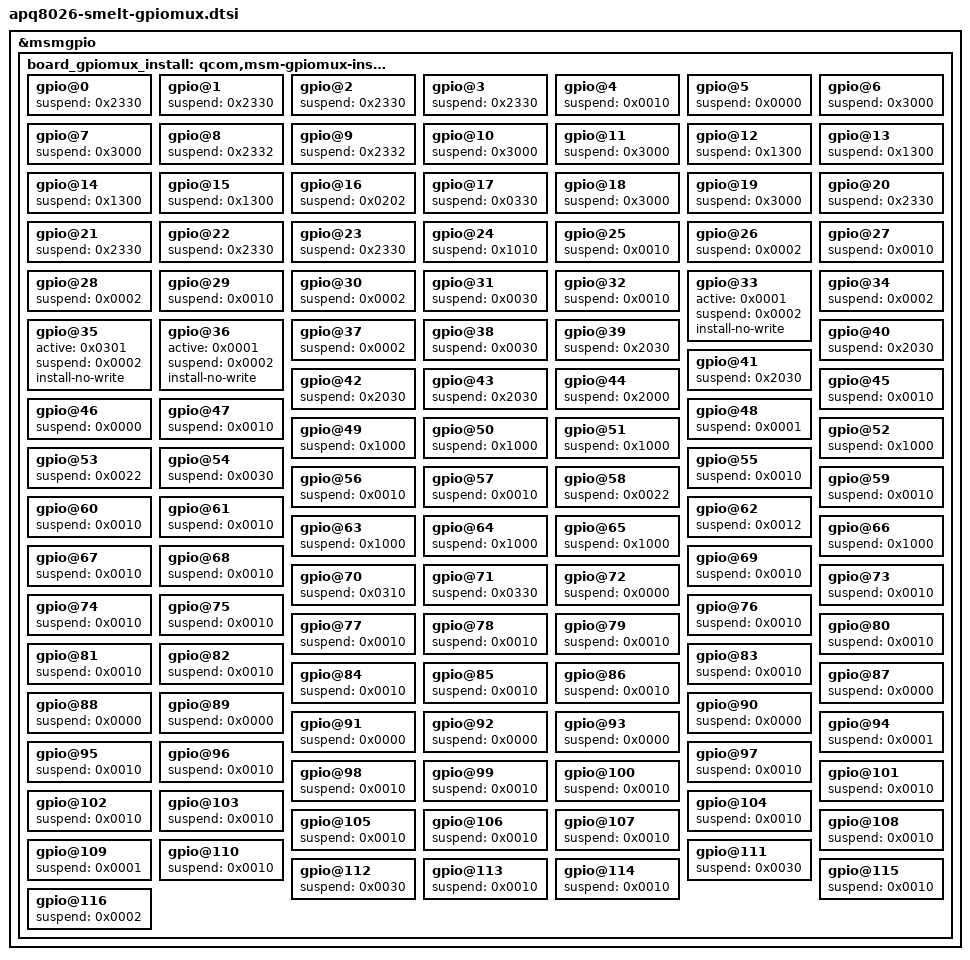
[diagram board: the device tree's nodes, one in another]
/* Copyright (c) 2014, The Linux Foundation. All rights reserved.
 *
 * This program is free software; you can redistribute it and/or modify
 * it under the terms of the GNU General Public License version 2 and
 * only version 2 as published by the Free Software Foundation.
 *
 * This program is distributed in the hope that it will be useful,
 * but WITHOUT ANY WARRANTY; without even the implied warranty of
 * MERCHANTABILITY or FITNESS FOR A PARTICULAR PURPOSE.  See the
 * GNU General Public License for more details.
 */

&msmgpio {
	/* board gpiomux initialization
	 * each node format is:
	 *   gpio-xx {
	 *     active = < gpio_settings >;
	 *     suspend = < gpio_settings >;
	 *     install-no-write;
	 *   };
	 * which xx is gpio digit number which needed to set.
	 *   active is the settings when gpio is requested.
	 *   suspend is the settings when gpio is freed. and gpiomux-install
	 *     will write suspend_settings as there is not any gpio had been
	 *     requested at beginning.
	 *   install-no-write is bool that indicates not change current state
	 *     of hardware, which is needed for some case like display, it
	 *     needs keep current settings from boot-loader
	 * gpio_settings is 16 bits hex like 0xFVPD, please refer kernel code
	 *   definition in gpiomux.h
	 *   'D' bits 0-3 is gpio direction and value, which
	 *       0 = input, 1 = output high, 2 = output low,
	 *   'P' bits 4-7 is gpio pull method, which
	 *       0 = none, 1 = pull down, 2 = pull keeper, 3 = pull up,
	 *   'V' bits 8-11 is gpio driven, which
	 *       0 = 2 mA, 1 = 4 mA, n = (n+1)*2 mA, the maximum is 16mA
	 *   'F' bits 12-15 is gpio function, which
	 *       0 = gpio, others refer hardware reference
	 * Example:
	 *
	 */
	board_gpiomux_install: qcom,msm-gpiomux-install {
		gpio@0 {
			suspend = <0x2330>; /* FUNC_2, DRV_8MA, PULL_UP, IN */
		};
		gpio@1 {
			suspend = <0x2330>; /* FUNC_2, DRV_8MA, PULL_UP, IN */
		};
		gpio@2 {
			suspend = <0x2330>; /* FUNC_2, DRV_8MA, PULL_UP, IN */
		};
		gpio@3 {
			suspend = <0x2330>; /* FUNC_2, DRV_8MA, PULL_UP, IN */
		};
		gpio@4 {
			suspend = <0x0010>; /* FUNC_GPIO, DRV_2MA, PULL_DOWN, IN */
		};
		gpio@5 {
			suspend = <0x0000>; /* FUNC_GPIO, DRV_2MA, PULL_NONE, IN */
		};
		gpio@6 {
			suspend = <0x3000>; /* FUNC_3, DRV_2MA, PULL_NONE, IN */
		};
		gpio@7 {
			suspend = <0x3000>; /* FUNC_3, DRV_2MA, PULL_NONE, IN */
		};
		gpio@8 {
			suspend = <0x2332>; /* FUNC_2, DRV_8MA, PULL_UP, OUT_LOW */
		};
		gpio@9 {
			suspend = <0x2332>; /* FUNC_2, DRV_8MA, PULL_UP, OUT_LOW */
		};
		gpio@10 {
			suspend = <0x3000>; /* FUNC_3, DRV_2MA, PULL_NONE, IN */
		};
		gpio@11 {
			suspend = <0x3000>; /* FUNC_3, DRV_2MA, PULL_NONE, IN */
		};
		gpio@12 {
			suspend = <0x1300>; /* FUNC_1, DRV_8MA, PULL_NONE, IN */
		};
		gpio@13 {
			suspend = <0x1300>; /* FUNC_1, DRV_8MA, PULL_NONE, IN */
		};
		gpio@14 {
			suspend = <0x1300>; /* FUNC_1, DRV_8MA, PULL_NONE, IN */
		};
		gpio@15 {
			suspend = <0x1300>; /* FUNC_1, DRV_8MA, PULL_NONE, IN */
		};
		gpio@16 {
			suspend = <0x0202>; /* FUNC_GPIO, DRV_6MA, PULL_NONE, OUT_LOW */
		};
		gpio@17 {
			suspend = <0x0330>; /* FUNC_GPIO, DRV_8MA, PULL_UP, IN */
		};
		gpio@18 {
			suspend = <0x3000>; /* FUNC_3, DRV_2MA, PULL_NONE, IN */
		};
		gpio@19 {
			suspend = <0x3000>; /* FUNC_3, DRV_2MA, PULL_NONE, IN */
		};
		gpio@20 {
			suspend = <0x2330>; /* FUNC_2, DRV_8MA, PULL_UP, IN */
		};
		gpio@21 {
			suspend = <0x2330>; /* FUNC_2, DRV_8MA, PULL_UP, IN */
		};
		gpio@22 {
			suspend = <0x2330>; /* FUNC_2, DRV_8MA, PULL_UP, IN */
		};
		gpio@23 {
			suspend = <0x2330>; /* FUNC_2, DRV_8MA, PULL_UP, IN */
		};
		gpio@24 {
			suspend = <0x1010>; /* FUNC_1, DRV_2MA, PULL_DOWN, IN */
		};
		gpio@25 {
			suspend = <0x0010>; /* FUNC_GPIO, DRV_2MA, PULL_DOWN, IN */
		};
		gpio@26 {
			suspend = <0x0002>; /* FUNC_GPIO, DRV_2MA, PULL_NONE, OUT_LOW */
		};
		gpio@27 {
			suspend = <0x0010>; /* FUNC_GPIO, DRV_2MA, PULL_DOWN, IN */
		};
		gpio@28 {
			suspend = <0x0002>; /* FUNC_GPIO, DRV_2MA, PULL_NONE, OUT_LOW */
		};
		gpio@29 {
			suspend = <0x0010>; /* FUNC_GPIO, DRV_2MA, PULL_DOWN, IN */
		};
		gpio@30 {
			suspend = <0x0002>; /* FUNC_GPIO, DRV_2MA, PULL_NONE, OUT_LOW */
		};
		gpio@31 {
			suspend = <0x0030>; /* FUNC_GPIO, DRV_2MA, PULL_UP, IN */
		};
		gpio@32 {
			suspend = <0x0010>; /* FUNC_GPIO, DRV_2MA, PULL_DOWN, IN */
		};
		gpio@33 {
			active  = <0x0001>; /* FUNC_GPIO, DRV_2MA, PULL_NONE, OUT_HIGH */
			suspend = <0x0002>; /* FUNC_GPIO, DRV_2MA, PULL_NONE, OUT_LOW */
			install-no-write;
		};
		gpio@34 {
			suspend = <0x0002>; /* FUNC_GPIO, DRV_2MA, PULL_NONE, OUT_LOW */
		};
		gpio@35 {
			active  = <0x0301>; /* FUNC_GPIO, DRV_8MA, PULL_NONE, OUT_HIGH */
			suspend = <0x0002>; /* FUNC_GPIO, DRV_2MA, PULL_NONE, OUT_LOW */
			install-no-write;
		};
		gpio@36 {
			active  = <0x0001>; /* FUNC_GPIO, DRV_2MA, PULL_NONE, OUT_HIGH */
			suspend = <0x0002>; /* FUNC_GPIO, DRV_2MA, PULL_NONE, OUT_LOW */
			install-no-write;
		};
		gpio@37 {
			suspend = <0x0002>; /* FUNC_GPIO, DRV_2MA, PULL_NONE, OUT_LOW */
		};
		gpio@38 {
			suspend = <0x0030>; /* FUNC_GPIO, DRV_2MA, PULL_UP, IN */
		};
		gpio@39 {
			suspend = <0x2030>; /* FUNC_2, DRV_2MA, PULL_UP, IN */
		};
		gpio@40 {
			suspend = <0x2030>; /* FUNC_2, DRV_2MA, PULL_UP, IN */
		};
		gpio@41 {
			suspend = <0x2030>; /* FUNC_2, DRV_2MA, PULL_UP, IN */
		};
		gpio@42 {
			suspend = <0x2030>; /* FUNC_2, DRV_2MA, PULL_UP, IN */
		};
		gpio@43 {
			suspend = <0x2030>; /* FUNC_2, DRV_2MA, PULL_UP, IN */
		};
		gpio@44 {
			suspend = <0x2000>; /* FUNC_2, DRV_2MA, PULL_NONE, IN */
		};
		gpio@45 {
			suspend = <0x0010>; /* FUNC_GPIO, DRV_2MA, PULL_DOWN, IN */
		};
		gpio@46 {
			suspend = <0x0000>; /* FUNC_GPIO, DRV_2MA, PULL_NONE, IN */
		};
		gpio@47 {
			suspend = <0x0010>; /* FUNC_GPIO, DRV_2MA, PULL_DOWN, IN */
		};
		gpio@48 {
			suspend = <0x0001>; /* FUNC_GPIO, DRV_2MA, PULL_NONE, OUT_HIGH */
		};
		gpio@49 {
			suspend = <0x1000>; /* FUNC_1, DRV_2MA, PULL_NONE, IN */
		};
		gpio@50 {
			suspend = <0x1000>; /* FUNC_1, DRV_2MA, PULL_NONE, IN */
		};
		gpio@51 {
			suspend = <0x1000>; /* FUNC_1, DRV_2MA, PULL_NONE, IN */
		};
		gpio@52 {
			suspend = <0x1000>; /* FUNC_1, DRV_2MA, PULL_NONE, IN */
		};
		gpio@53 {
			suspend = <0x0022>; /* FUNC_GPIO, DRV_2MA, PULL_KEEPER, OUT_LOW */
		};
		gpio@54 {
			suspend = <0x0030>; /* FUNC_GPIO, DRV_2MA, PULL_UP, IN */
		};
		gpio@55 {
			suspend = <0x0010>; /* FUNC_GPIO, DRV_2MA, PULL_DOWN, IN */
		};
		gpio@56 {
			suspend = <0x0010>; /* FUNC_GPIO, DRV_2MA, PULL_DOWN, IN */
		};
		gpio@57 {
			suspend = <0x0010>; /* FUNC_GPIO, DRV_2MA, PULL_DOWN, IN */
		};
		gpio@58 {
			suspend = <0x0022>; /* FUNC_GPIO, DRV_2MA, PULL_KEEPER, OUT_LOW */
		};
		gpio@59 {
			suspend = <0x0010>; /* FUNC_GPIO, DRV_2MA, PULL_DOWN, IN */
		};
		gpio@60 {
			suspend = <0x0010>; /* FUNC_GPIO, DRV_2MA, PULL_DOWN, IN */
		};
		gpio@61 {
			suspend = <0x0010>; /* FUNC_GPIO, DRV_2MA, PULL_DOWN, IN */
		};
		gpio@62 {
			suspend = <0x0012>; /* FUNC_GPIO, DRV_2MA, PULL_DOWN, OUT_LOW */
		};
		gpio@63 {
			suspend = <0x1000>; /* FUNC_1, DRV_2MA, PULL_NONE, IN */
		};
		gpio@64 {
			suspend = <0x1000>; /* FUNC_1, DRV_2MA, PULL_NONE, IN */
		};
		gpio@65 {
			suspend = <0x1000>; /* FUNC_1, DRV_2MA, PULL_NONE, IN */
		};
		gpio@66 {
			suspend = <0x1000>; /* FUNC_1, DRV_2MA, PULL_NONE, IN */
		};
		gpio@67 {
			suspend = <0x0010>; /* FUNC_GPIO, DRV_2MA, PULL_DOWN, IN */
		};
		gpio@68 {
			suspend = <0x0010>; /* FUNC_GPIO, DRV_2MA, PULL_DOWN, IN */
		};
		gpio@69 {
			suspend = <0x0010>; /* FUNC_GPIO, DRV_2MA, PULL_DOWN, IN */
		};
		gpio@70 {
			suspend = <0x0310>; /* FUNC_GPIO, DRV_8MA, PULL_DOWN, IN */
		};
		gpio@71 {
			suspend = <0x0330>; /* FUNC_GPIO, DRV_8MA, PULL_UP, IN */
		};
		gpio@72 {
			suspend = <0x0000>; /* FUNC_GPIO, DRV_2MA, PULL_NONE, IN */
		};
		gpio@73 {
			suspend = <0x0010>; /* FUNC_GPIO, DRV_2MA, PULL_DOWN, IN */
		};
		gpio@74 {
			suspend = <0x0010>; /* FUNC_GPIO, DRV_2MA, PULL_DOWN, IN */
		};
		gpio@75 {
			suspend = <0x0010>; /* FUNC_GPIO, DRV_2MA, PULL_DOWN, IN */
		};
		gpio@76 {
			suspend = <0x0010>; /* FUNC_GPIO, DRV_2MA, PULL_DOWN, IN */
		};
		gpio@77 {
			suspend = <0x0010>; /* FUNC_GPIO, DRV_2MA, PULL_DOWN, IN */
		};
		gpio@78 {
			suspend = <0x0010>; /* FUNC_GPIO, DRV_2MA, PULL_DOWN, IN */
		};
		gpio@79 {
			suspend = <0x0010>; /* FUNC_GPIO, DRV_2MA, PULL_DOWN, IN */
		};
		gpio@80 {
			suspend = <0x0010>; /* FUNC_GPIO, DRV_2MA, PULL_DOWN, IN */
		};
		gpio@81 {
			suspend = <0x0010>; /* FUNC_GPIO, DRV_2MA, PULL_DOWN, IN */
		};
		gpio@82 {
			suspend = <0x0010>; /* FUNC_GPIO, DRV_2MA, PULL_DOWN, IN */
		};
		gpio@83 {
			suspend = <0x0010>; /* FUNC_GPIO, DRV_2MA, PULL_DOWN, IN */
		};
		gpio@84 {
			suspend = <0x0010>; /* FUNC_GPIO, DRV_2MA, PULL_DOWN, IN */
		};
		gpio@85 {
			suspend = <0x0010>; /* FUNC_GPIO, DRV_2MA, PULL_DOWN, IN */
		};
		gpio@86 {
			suspend = <0x0010>; /* FUNC_GPIO, DRV_2MA, PULL_DOWN, IN */
		};
		gpio@87 {
			suspend = <0x0000>; /* FUNC_GPIO, DRV_2MA, PULL_NONE, IN */
		};
		gpio@88 {
			suspend = <0x0000>; /* FUNC_GPIO, DRV_2MA, PULL_NONE, IN */
		};
		gpio@89 {
			suspend = <0x0000>; /* FUNC_GPIO, DRV_2MA, PULL_NONE, IN */
		};
		gpio@90 {
			suspend = <0x0000>; /* FUNC_GPIO, DRV_2MA, PULL_NONE, IN */
		};
		gpio@91 {
			suspend = <0x0000>; /* FUNC_GPIO, DRV_2MA, PULL_NONE, IN */
		};
		gpio@92 {
			suspend = <0x0000>; /* FUNC_GPIO, DRV_2MA, PULL_NONE, IN */
		};
		gpio@93 {
			suspend = <0x0000>; /* FUNC_GPIO, DRV_2MA, PULL_NONE, IN */
		};
		gpio@94 {
			suspend = <0x0001>; /* FUNC_GPIO, DRV_2MA, PULL_NONE, OUT_HIGH */
		};
		gpio@95 {
			suspend = <0x0010>; /* FUNC_GPIO, DRV_2MA, PULL_DOWN, IN */
		};
		gpio@96 {
			suspend = <0x0010>; /* FUNC_GPIO, DRV_2MA, PULL_DOWN, IN */
		};
		gpio@97 {
			suspend = <0x0010>; /* FUNC_GPIO, DRV_2MA, PULL_DOWN, IN */
		};
		gpio@98 {
			suspend = <0x0010>; /* FUNC_GPIO, DRV_2MA, PULL_DOWN, IN */
		};
		gpio@99 {
			suspend = <0x0010>; /* FUNC_GPIO, DRV_2MA, PULL_DOWN, IN */
		};
		gpio@100 {
			suspend = <0x0010>; /* FUNC_GPIO, DRV_2MA, PULL_DOWN, IN */
		};
		gpio@101 {
			suspend = <0x0010>; /* FUNC_GPIO, DRV_2MA, PULL_DOWN, IN */
		};
		gpio@102 {
			suspend = <0x0010>; /* FUNC_GPIO, DRV_2MA, PULL_DOWN, IN */
		};
		gpio@103 {
			suspend = <0x0010>; /* FUNC_GPIO, DRV_2MA, PULL_DOWN, IN */
		};
		gpio@104 {
			suspend = <0x0010>; /* FUNC_GPIO, DRV_2MA, PULL_DOWN, IN */
		};
		gpio@105 {
			suspend = <0x0010>; /* FUNC_GPIO, DRV_2MA, PULL_DOWN, IN */
		};
		gpio@106 {
			suspend = <0x0010>; /* FUNC_GPIO, DRV_2MA, PULL_DOWN, IN */
		};
		gpio@107 {
			suspend = <0x0010>; /* FUNC_GPIO, DRV_2MA, PULL_DOWN, IN */
		};
		gpio@108 {
			suspend = <0x0010>; /* FUNC_GPIO, DRV_2MA, PULL_DOWN, IN */
		};
		gpio@109 {
			suspend = <0x0001>; /* FUNC_GPIO, DRV_2MA, PULL_NONE, OUT_HIGH */
		};
		gpio@110 {
			suspend = <0x0010>; /* FUNC_GPIO, DRV_2MA, PULL_DOWN, IN */
		};
		gpio@111 {
			suspend = <0x0030>; /* FUNC_GPIO, DRV_2MA, PULL_UP, IN */
		};
		gpio@112 {
			suspend = <0x0030>; /* FUNC_GPIO, DRV_2MA, PULL_UP, IN */
		};
		gpio@113 {
			suspend = <0x0010>; /* FUNC_GPIO, DRV_2MA, PULL_DOWN, IN */
		};
		gpio@114 {
			suspend = <0x0010>; /* FUNC_GPIO, DRV_2MA, PULL_DOWN, IN */
		};
		gpio@115 {
			suspend = <0x0010>; /* FUNC_GPIO, DRV_2MA, PULL_DOWN, IN */
		};
		gpio@116 {
			suspend = <0x0002>; /* FUNC_GPIO, DRV_2MA, PULL_NONE, OUT_LOW */
		};
	};
};
